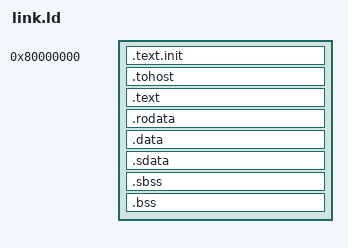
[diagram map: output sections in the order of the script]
OUTPUT_ARCH("riscv")
ENTRY(_start)

PHDRS
{
  text PT_LOAD FLAGS(5);
}

SECTIONS
{
  . = 0x80000000;
  .text.init : { *(.text.init) } : text

  . = ALIGN(0x1000);
  .tohost : { *(.tohost) }

  . = ALIGN(0x1000);
  .text : { *(.text .text.*) } : text
  .rodata : { *(.rodata .rodata.*) }

  .data : { *(.data .data.*) }

  .sdata : {
    __global_pointer$ = . + 0x800;
    *(.srodata.cst16) *(.srodata.cst8) *(.srodata.cst4) *(.srodata.cst2)
    *(.srodata*)
    *(.sdata .sdata.* .gnu.linkonce.s.*)
  }

  .sbss : {
    *(.sbss .sbss.* .gnu.linkonce.sb.*)
    *(.scommon)
  }

  .bss : {
    *(.bss .bss.*)
    *(COMMON)
  }

  . = ALIGN(16);
  _end = .;

  . = ALIGN(16);
  . += 16K;
  _stack_top = .;
}
